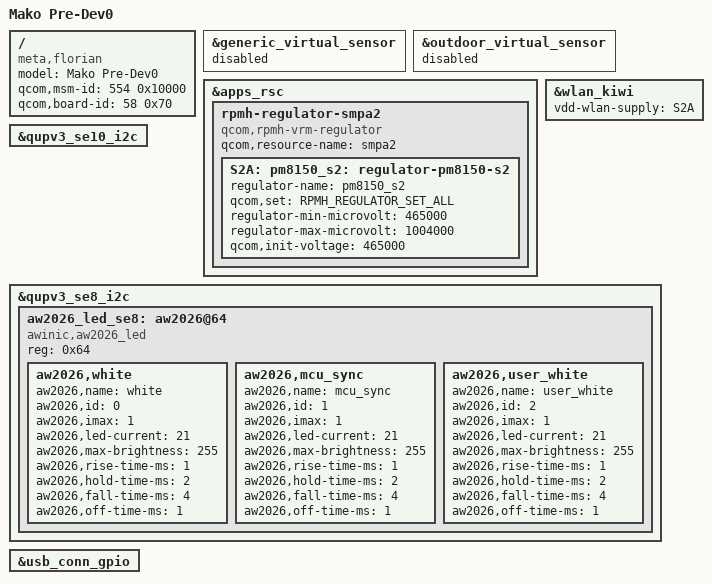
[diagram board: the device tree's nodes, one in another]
/dts-v1/;
/plugin/;

#include "mako.dtsi"

/ {
	model = "Mako Pre-Dev0";
	compatible = "meta,florian", "meta,mako", "meta,mako-pre-dev0";
	qcom,msm-id = <554 0x10000>;
	qcom,board-id = <58 0x70>;
};

&generic_virtual_sensor {
        status = "disabled";
};

&outdoor_virtual_sensor {
	status = "disabled";
};

&apps_rsc {
	rpmh-regulator-smpa2 {
		compatible = "qcom,rpmh-vrm-regulator";
		qcom,resource-name = "smpa2";
		S2A: pm8150_s2: regulator-pm8150-s2 {
			regulator-name = "pm8150_s2";
			qcom,set = <RPMH_REGULATOR_SET_ALL>;
			regulator-min-microvolt = <465000>;
			regulator-max-microvolt = <1004000>;
			qcom,init-voltage = <465000>;
		};
	};
};

&wlan_kiwi {
	vdd-wlan-supply = <&S2A>;
};

&qupv3_se10_i2c {
	/delete-node/ aw2026_led;
};

&qupv3_se8_i2c {
	aw2026_led_se8: aw2026@64 {
		compatible = "awinic,aw2026_led";
		reg = <0x64>;
		status = "ok";

		aw2026,white {
			aw2026,name = "white";
			aw2026,id = <0>;
			aw2026,imax = <1>;
			aw2026,led-current = <21>;
			aw2026,max-brightness = <255>;
			aw2026,rise-time-ms = <1>;
			aw2026,hold-time-ms = <2>;
			aw2026,fall-time-ms = <4>;
			aw2026,off-time-ms = <1>;
		};

		aw2026,mcu_sync {
				aw2026,name = "mcu_sync";
				aw2026,id = <1>;
				aw2026,imax = <1>;
				aw2026,led-current = <21>;
				aw2026,max-brightness = <255>;
				aw2026,rise-time-ms = <1>;
				aw2026,hold-time-ms = <2>;
				aw2026,fall-time-ms = <4>;
				aw2026,off-time-ms = <1>;
		};

		aw2026,user_white {
				aw2026,name = "user_white";
				aw2026,id = <2>;
				aw2026,imax = <1>;
				aw2026,led-current = <21>;
				aw2026,max-brightness = <255>;
				aw2026,rise-time-ms = <1>;
				aw2026,hold-time-ms = <2>;
				aw2026,fall-time-ms = <4>;
				aw2026,off-time-ms = <1>;
		};
	};
};

&usb_conn_gpio {
	/delete-property/ meta,enable-vchrg-debug-detect;
};
